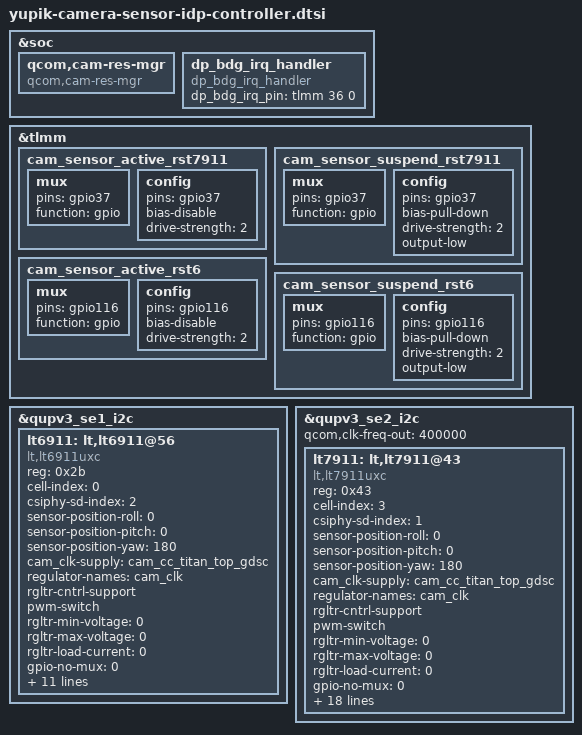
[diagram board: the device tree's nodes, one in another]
// SPDX-License-Identifier: BSD-3-Clause
/*
 * Copyright (c) Qualcomm Technologies, Inc. and/or its subsidiaries.
 */
#include <dt-bindings/msm-camera.h>

&soc {
	qcom,cam-res-mgr {
		compatible = "qcom,cam-res-mgr";
		status = "ok";
	};
};

&tlmm {
		cam_sensor_active_rst7911: cam_sensor_active_rst7911 {
			/* RESET 7911 */
			mux {
				pins = "gpio37";
				function = "gpio";
			};

			config {
				pins = "gpio37";
				bias-disable; /* No PULL */
				drive-strength = <2>; /* 2 MA */
			};
		};

		cam_sensor_suspend_rst7911: cam_sensor_suspend_rst7911 {
			/* RESET 7911 */
			mux {
				pins = "gpio37";
				function = "gpio";
			};

			config {
				pins = "gpio37";
				bias-pull-down; /* PULL DOWN */
				drive-strength = <2>; /* 2 MA */
				output-low;
			};
		};

		cam_sensor_active_rst6: cam_sensor_active_rst6 {
			/* RESET 6 */
			mux {
				pins = "gpio116";
				function = "gpio";
			};

			config {
				pins = "gpio116";
				bias-disable; /* No PULL */
				drive-strength = <2>; /* 2 MA */
			};
		};

		cam_sensor_suspend_rst6: cam_sensor_suspend_rst6 {
			/* RESET 6 */
			mux {
				pins = "gpio116";
				function = "gpio";
			};

			config {
				pins = "gpio116";
				bias-pull-down; /* PULL DOWN */
				drive-strength = <2>; /* 2 MA */
				output-low;
			};
		};
};

/*lt6911uxc-hdmi*/
&qupv3_se1_i2c {
	status = "ok";
	lt6911: lt,lt6911@56 {
		compatible = "lt,lt6911uxc";
		reg = <0x2b>;
		cell-index = <0>;
		csiphy-sd-index = <2>;
		sensor-position-roll = <0>;
		sensor-position-pitch = <0>;
		sensor-position-yaw = <180>;
		cam_clk-supply = <&cam_cc_titan_top_gdsc>;
		regulator-names = "cam_clk";
		rgltr-cntrl-support;
		pwm-switch;
		rgltr-min-voltage = <0>;
		rgltr-max-voltage = <0>;
		rgltr-load-current = <0>;
		gpio-no-mux = <0>;
		pinctrl-names = "cam_default", "cam_suspend";
		pinctrl-0 = <&cam_sensor_active_rst6>;
		pinctrl-1 = <&cam_sensor_suspend_rst6>;
		gpios = <&tlmm 116 0>;
		gpio-reset = <0>;
		gpio-req-tbl-num = <0>;
		gpio-req-tbl-flags = <0>;
		gpio-req-tbl-label = "HDMI_RESET0";
		sensor-mode = <0>;
		clocks = <&camcc CAM_CC_MCLK3_CLK>;
		clock-names = "cam_clk";
		clock-cntl-level = "turbo";
		clock-rates = <24000000>;
	};
};

/*lt7911uxc-dp*/
&qupv3_se2_i2c {
	status = "ok";
	qcom,clk-freq-out = <400000>;
	lt7911: lt,lt7911@43 {
		compatible = "lt,lt7911uxc";
		reg = <0x43>;
		cell-index = <3>;
		csiphy-sd-index = <1>;
		sensor-position-roll = <0>;
		sensor-position-pitch = <0>;
		sensor-position-yaw = <180>;
		cam_clk-supply = <&cam_cc_titan_top_gdsc>;
		regulator-names = "cam_clk";
		rgltr-cntrl-support;
		pwm-switch;
		rgltr-min-voltage = <0>;
		rgltr-max-voltage = <0>;
		rgltr-load-current = <0>;
		gpio-no-mux = <0>;
		pinctrl-names = "cam_default", "cam_suspend";
		pinctrl-0 = <&cam_sensor_active_pwr1p17911
					 &cam_sensor_active_pwr3p37911
					 &cam_sensor_active_rst7911>;
		pinctrl-1 = <&cam_sensor_suspend_pwr3p37911
					 &cam_sensor_suspend_pwr1p17911
					 &cam_sensor_suspend_rst7911>;
		gpios = <&tlmm 37 0>, <&tlmm 39 0>, <&tlmm 90 0>;
		gpio-reset = <0>;
        	gpio-standby = <1>;
        	gpio-custom1 = <2>;
		gpio-req-tbl-num = <0 1 2>;
		gpio-req-tbl-flags = <0 1 2>;
		gpio-req-tbl-label = "CAM_RESET3", "CAM_STANDBY", "CAM_CUSTOM1";
		sensor-mode = <0>;
		clocks = <&camcc CAM_CC_MCLK3_CLK>;
		clock-names = "cam_clk";
		clock-cntl-level = "turbo";
		clock-rates = <24000000>;
    };
};

&soc {
	dp_bdg_irq_handler: dp_bdg_irq_handler {
		compatible = "dp_bdg_irq_handler";
		dp_bdg_irq_pin = <&tlmm 36 0>;
	};
};

